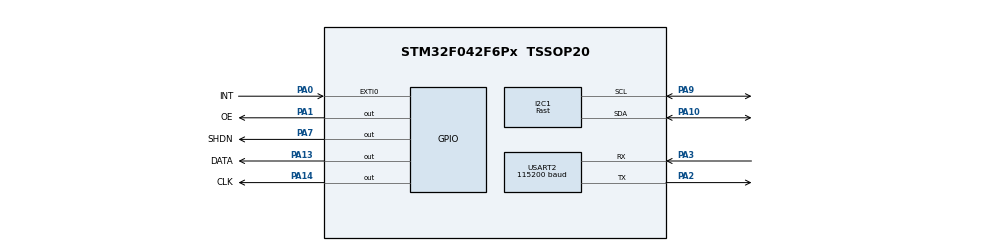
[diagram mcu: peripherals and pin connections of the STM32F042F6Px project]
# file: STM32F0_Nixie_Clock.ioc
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I2C1.I2C_Speed_Mode=I2C_Fast
I2C1.Timing=0x0000020B
Mcu.Family=STM32F0
Mcu.Name=STM32F042F6Px
Mcu.Package=TSSOP20
NVIC.EXTI0_1_IRQn=true\:0\:0\:false\:false\:true\:true\:true
PA0.GPIO_Label=INT
PA0.GPIO_ModeDefaultEXTI=GPIO_MODE_IT_FALLING
PA0.Signal=GPXTI0
PA1.GPIO_Label=OE
PA1.Signal=GPIO_Output
PA10.Mode=I2C
PA10.Signal=I2C1_SDA
PA13.GPIO_Label=DATA
PA13.Signal=GPIO_Output
PA14.GPIO_Label=CLK
PA14.Signal=GPIO_Output
PA2.Mode=Asynchronous
PA2.Signal=USART2_TX
PA3.Mode=Asynchronous
PA3.Signal=USART2_RX
PA7.GPIO_Label=SHDN
PA7.Signal=GPIO_Output
PA9.Mode=I2C
PA9.Signal=I2C1_SCL
ProjectManager.HeapSize=0x200
ProjectManager.StackSize=0x400
ProjectManager.TargetToolchain=STM32CubeIDE
TIM3.Period=0xffff - 1
TIM3.Prescaler=8 - 1
USART2.BaudRate=115200
USART2.VirtualMode-Asynchronous=VM_ASYNC
VP_TIM3_VS_ClockSourceINT.Mode=Internal
board=custom

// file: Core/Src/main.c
/* USER CODE BEGIN Header */
/**
 ******************************************************************************
 * @file           : main.c
 * @brief          : Main program body
 ******************************************************************************
 * @attention
 *
 * <h2><center>&copy; Copyright (c) 2021 STMicroelectronics.
 * All rights reserved.</center></h2>
 *
 * This software component is licensed by ST under BSD 3-Clause license,
 * the "License"; You may not use this file except in compliance with the
 * License. You may obtain a copy of the License at:
 *                        opensource.org/licenses/BSD-3-Clause
 *
 ******************************************************************************
 */
/* USER CODE END Header */

#include "main.h"

/* USER CODE BEGIN Includes */
#include "lib/rtc/ds3231_for_stm32_hal.h"
#include "lib/sr/nixie.h"
/* USER CODE END Includes */

I2C_HandleTypeDef hi2c1;

TIM_HandleTypeDef htim3;

UART_HandleTypeDef huart2;

void SystemClock_Config(void);
static void MX_GPIO_Init(void);
static void MX_I2C1_Init(void);
static void MX_USART2_UART_Init(void);
static void MX_TIM3_Init(void);

int main(void) {

	/* MCU Configuration--------------------------------------------------------*/

	/* Reset of all peripherals, Initializes the Flash interface and the Systick. */
	HAL_Init();

	/* Configure the system clock */
	SystemClock_Config();

	/* Initialize all configured peripherals */
	MX_GPIO_Init();
	MX_I2C1_Init();
	MX_USART2_UART_Init();
	MX_TIM3_Init();
	/* USER CODE BEGIN 2 */
	__disable_irq();
	Nixie_Init(&hi2c1, &htim3);
	Nixie_SetDebugUART(&huart2);
	NIXIE_POWER_UP;
	NIXIE_OUTPUT_ENABLED;
	__enable_irq();
	/* USER CODE END 2 */

	/* Infinite loop */
	while (1) {

	}
}

void SystemClock_Config(void) {
	RCC_OscInitTypeDef RCC_OscInitStruct = { 0 };
	RCC_ClkInitTypeDef RCC_ClkInitStruct = { 0 };
	RCC_PeriphCLKInitTypeDef PeriphClkInit = { 0 };

	/** Initializes the CPU, AHB and APB busses clocks
	 */
	RCC_OscInitStruct.OscillatorType = RCC_OSCILLATORTYPE_HSI;
	RCC_OscInitStruct.HSIState = RCC_HSI_ON;
	RCC_OscInitStruct.HSICalibrationValue = RCC_HSICALIBRATION_DEFAULT;
	RCC_OscInitStruct.PLL.PLLState = RCC_PLL_NONE;
	if (HAL_RCC_OscConfig(&RCC_OscInitStruct) != HAL_OK) {
		Error_Handler();
	}
	/** Initializes the CPU, AHB and APB busses clocks
	 */
	RCC_ClkInitStruct.ClockType = RCC_CLOCKTYPE_HCLK | RCC_CLOCKTYPE_SYSCLK
			| RCC_CLOCKTYPE_PCLK1;
	RCC_ClkInitStruct.SYSCLKSource = RCC_SYSCLKSOURCE_HSI;
	RCC_ClkInitStruct.AHBCLKDivider = RCC_SYSCLK_DIV1;
	RCC_ClkInitStruct.APB1CLKDivider = RCC_HCLK_DIV1;

	if (HAL_RCC_ClockConfig(&RCC_ClkInitStruct, FLASH_LATENCY_0) != HAL_OK) {
		Error_Handler();
	}
	PeriphClkInit.PeriphClockSelection = RCC_PERIPHCLK_I2C1;
	PeriphClkInit.I2c1ClockSelection = RCC_I2C1CLKSOURCE_HSI;
	if (HAL_RCCEx_PeriphCLKConfig(&PeriphClkInit) != HAL_OK) {
		Error_Handler();
	}
}

static void MX_I2C1_Init(void) {

	hi2c1.Instance = I2C1;
	hi2c1.Init.Timing = 0x0000020B;
	hi2c1.Init.OwnAddress1 = 0;
	hi2c1.Init.AddressingMode = I2C_ADDRESSINGMODE_7BIT;
	hi2c1.Init.DualAddressMode = I2C_DUALADDRESS_DISABLE;
	hi2c1.Init.OwnAddress2 = 0;
	hi2c1.Init.OwnAddress2Masks = I2C_OA2_NOMASK;
	hi2c1.Init.GeneralCallMode = I2C_GENERALCALL_DISABLE;
	hi2c1.Init.NoStretchMode = I2C_NOSTRETCH_DISABLE;
	if (HAL_I2C_Init(&hi2c1) != HAL_OK) {
		Error_Handler();
	}
	/** Configure Analogue filter
	 */
	if (HAL_I2CEx_ConfigAnalogFilter(&hi2c1, I2C_ANALOGFILTER_ENABLE)
			!= HAL_OK) {
		Error_Handler();
	}
	/** Configure Digital filter
	 */
	if (HAL_I2CEx_ConfigDigitalFilter(&hi2c1, 0) != HAL_OK) {
		Error_Handler();
	}

}

static void MX_TIM3_Init(void) {

	TIM_ClockConfigTypeDef sClockSourceConfig = { 0 };
	TIM_MasterConfigTypeDef sMasterConfig = { 0 };

	htim3.Instance = TIM3;
	htim3.Init.Prescaler = 8 - 1;
	htim3.Init.CounterMode = TIM_COUNTERMODE_UP;
	htim3.Init.Period = 0xffff - 1;
	htim3.Init.ClockDivision = TIM_CLOCKDIVISION_DIV1;
	htim3.Init.AutoReloadPreload = TIM_AUTORELOAD_PRELOAD_DISABLE;
	if (HAL_TIM_Base_Init(&htim3) != HAL_OK) {
		Error_Handler();
	}
	sClockSourceConfig.ClockSource = TIM_CLOCKSOURCE_INTERNAL;
	if (HAL_TIM_ConfigClockSource(&htim3, &sClockSourceConfig) != HAL_OK) {
		Error_Handler();
	}
	sMasterConfig.MasterOutputTrigger = TIM_TRGO_RESET;
	sMasterConfig.MasterSlaveMode = TIM_MASTERSLAVEMODE_DISABLE;
	if (HAL_TIMEx_MasterConfigSynchronization(&htim3, &sMasterConfig)
			!= HAL_OK) {
		Error_Handler();
	}

}

static void MX_USART2_UART_Init(void) {

	huart2.Instance = USART2;
	huart2.Init.BaudRate = 115200;
	huart2.Init.WordLength = UART_WORDLENGTH_8B;
	huart2.Init.StopBits = UART_STOPBITS_1;
	huart2.Init.Parity = UART_PARITY_NONE;
	huart2.Init.Mode = UART_MODE_TX_RX;
	huart2.Init.HwFlowCtl = UART_HWCONTROL_NONE;
	huart2.Init.OverSampling = UART_OVERSAMPLING_16;
	huart2.Init.OneBitSampling = UART_ONE_BIT_SAMPLE_DISABLE;
	huart2.AdvancedInit.AdvFeatureInit = UART_ADVFEATURE_NO_INIT;
	if (HAL_UART_Init(&huart2) != HAL_OK) {
		Error_Handler();
	}

}

static void MX_GPIO_Init(void) {
	GPIO_InitTypeDef GPIO_InitStruct = { 0 };

	/* GPIO Ports Clock Enable */
	__HAL_RCC_GPIOA_CLK_ENABLE();

	/*Configure GPIO pin Output Level */
	HAL_GPIO_WritePin(GPIOA, OE_Pin | SHDN_Pin | DATA_Pin | CLK_Pin,
			GPIO_PIN_RESET);

	/*Configure GPIO pin : INT_Pin */
	GPIO_InitStruct.Pin = INT_Pin;
	GPIO_InitStruct.Mode = GPIO_MODE_IT_FALLING;
	GPIO_InitStruct.Pull = GPIO_NOPULL;
	HAL_GPIO_Init(INT_GPIO_Port, &GPIO_InitStruct);

	/*Configure GPIO pins : OE_Pin SHDN_Pin DATA_Pin CLK_Pin */
	GPIO_InitStruct.Pin = OE_Pin | SHDN_Pin | DATA_Pin | CLK_Pin;
	GPIO_InitStruct.Mode = GPIO_MODE_OUTPUT_PP;
	GPIO_InitStruct.Pull = GPIO_NOPULL;
	GPIO_InitStruct.Speed = GPIO_SPEED_FREQ_LOW;
	HAL_GPIO_Init(GPIOA, &GPIO_InitStruct);

	/* EXTI interrupt init*/
	HAL_NVIC_SetPriority(EXTI0_1_IRQn, 0, 0);
	HAL_NVIC_EnableIRQ(EXTI0_1_IRQn);

}

void Error_Handler(void) {
}

/************************ (C) COPYRIGHT STMicroelectronics *****END OF FILE****/
